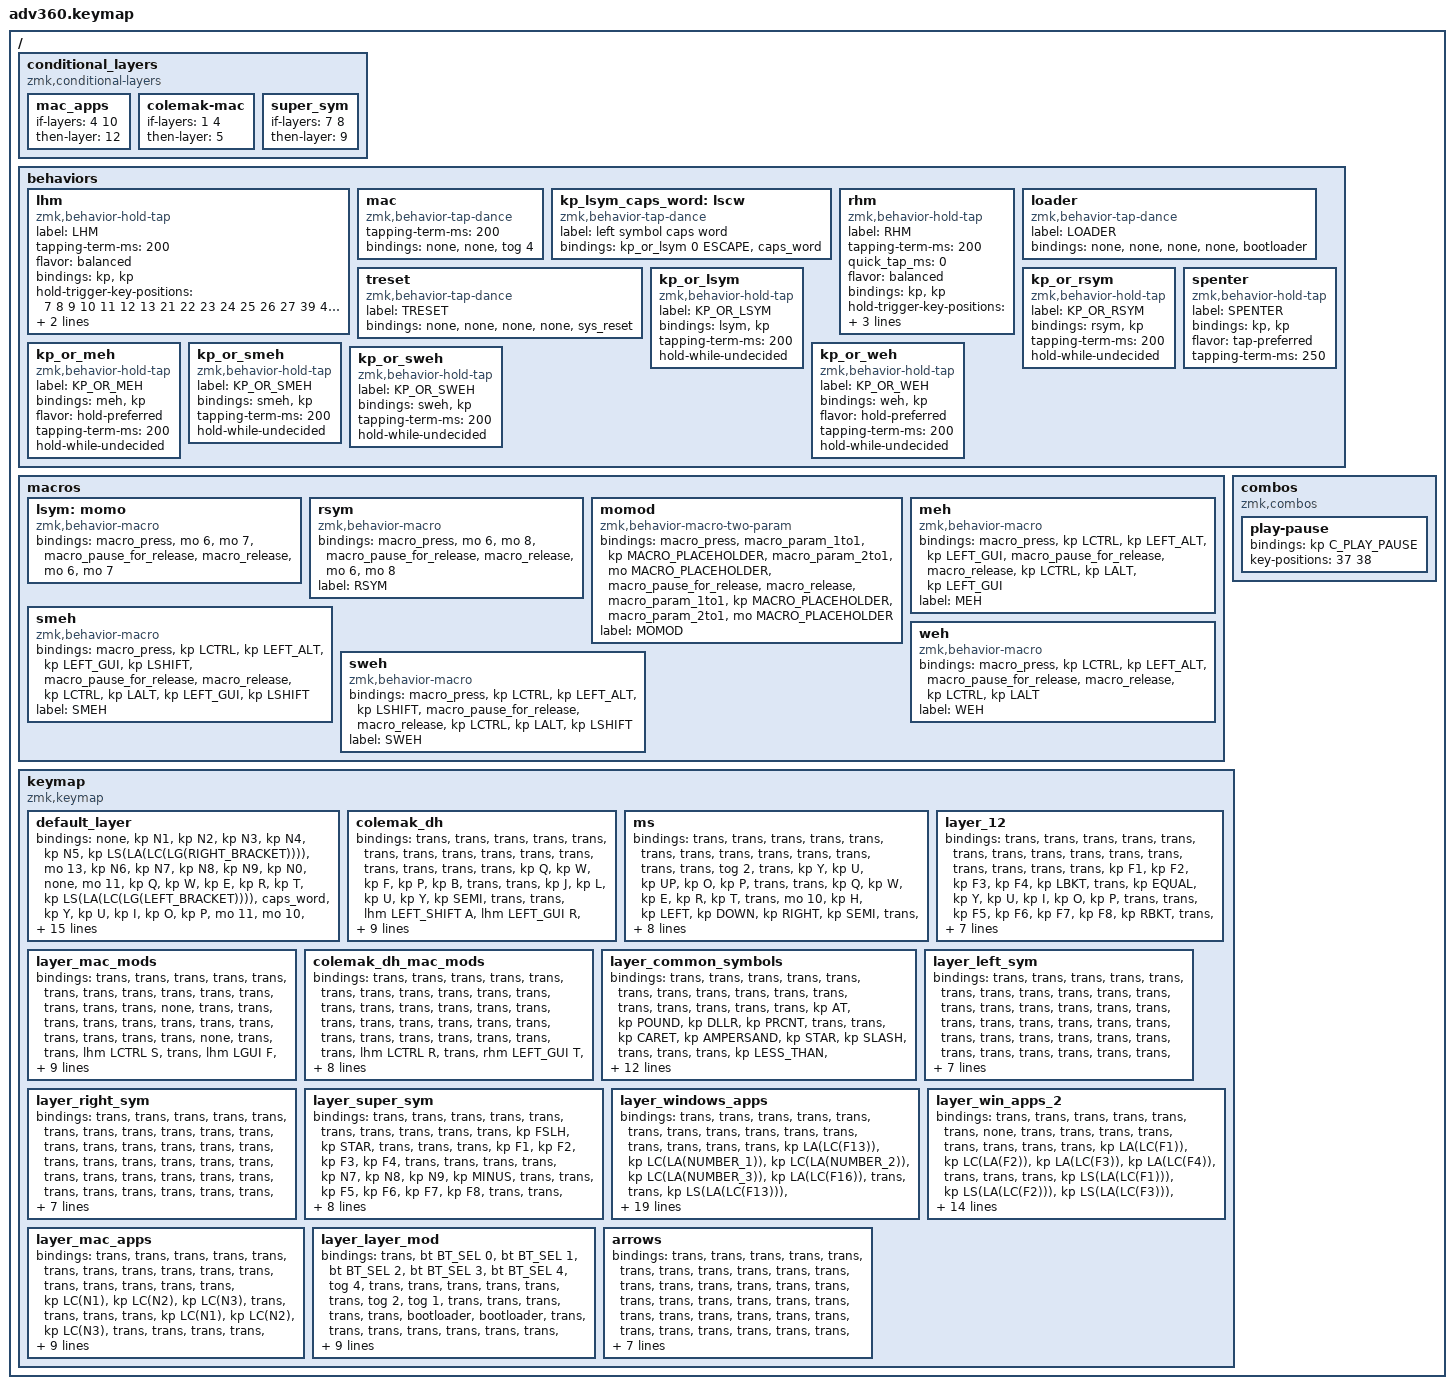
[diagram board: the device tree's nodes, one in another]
/*
 * Copyright (c) 2020 The ZMK Contributors
 *
 * SPDX-License-Identifier: MIT
 */
/* THIS FILE WAS GENERATED!
 *
 * This file was generated automatically. You may or may not want to
 * edit it directly.
 */

#include <behaviors.dtsi>
#include <dt-bindings/zmk/backlight.h>
#include <dt-bindings/zmk/bt.h>
#include <dt-bindings/zmk/keys.h>
#include <dt-bindings/zmk/rgb.h>

#define DEFAULT   0
#define MAC       1
#define SYM       2
#define LSYM      3
#define RSYM      4
#define ESYM      5
#define WINAPPS   6
#define MACAPPS   7
#define MOD       8

/ {
    conditional_layers {
        compatible = "zmk,conditional-layers";

        mac_apps {
            if-layers = <4 10>;
            then-layer = <12>;
        };

        colemak-mac {
            if-layers = <1 4>;
            then-layer = <5>;
        };

        super_sym {
            if-layers = <7 8>;
            then-layer = <9>;
        };
    };

    behaviors {
        lhm: lhm {
            compatible = "zmk,behavior-hold-tap";
            label = "LHM";
            #binding-cells = <2>;
            tapping-term-ms = <200>;
            flavor = "balanced";
            bindings = <&kp>, <&kp>;

            hold-trigger-key-positions = <7 8 9 10 11 12 13 21 22 23 24 25 26 27 39 40 41 42 43 44 45 54 55 56 57 58 59 71 72 73 74 75>;
            require-prior-idle-ms = <500>;
            quick-tap-ms = <175>;
        };

        mac: mac {
            compatible = "zmk,behavior-tap-dance";
            #binding-cells = <0>;
            tapping-term-ms = <200>;
            bindings = <&none>, <&none>, <&tog 4>;
        };

        kp_lsym_caps_word: lscw {
            compatible = "zmk,behavior-tap-dance";
            label = "left symbol caps word";
            #binding-cells = <0>;
            bindings = <&kp_or_lsym 0 ESCAPE>, <&caps_word>;
        };

        rhm: rhm {
            compatible = "zmk,behavior-hold-tap";
            label = "RHM";
            #binding-cells = <2>;
            tapping-term-ms = <200>;
            quick_tap_ms = <0>;
            flavor = "balanced";
            bindings = <&kp>, <&kp>;

            hold-trigger-key-positions = <0 1 2 3 4 5 6 16 17 18 19 20 14 15 16 17 18 19 20 28 29 30 31 32 33 34 46 47 48 49 50 51 60 61 62 63 64>;
            require-prior-idle-ms = <500>;
            quick-tap-ms = <175>;
        };

        loader: loader {
            compatible = "zmk,behavior-tap-dance";
            label = "LOADER";
            #binding-cells = <0>;
            bindings = <&none>, <&none>, <&none>, <&none>, <&bootloader>;
        };

        treset: treset {
            compatible = "zmk,behavior-tap-dance";
            label = "TRESET";
            #binding-cells = <0>;
            bindings = <&none>, <&none>, <&none>, <&none>, <&sys_reset>;
        };

        kp_or_lsym: kp_or_lsym {
            compatible = "zmk,behavior-hold-tap";
            label = "KP_OR_LSYM";
            bindings = <&lsym>, <&kp>;

            #binding-cells = <2>;
            tapping-term-ms = <200>;
            hold-while-undecided;
        };

        kp_or_rsym: kp_or_rsym {
            compatible = "zmk,behavior-hold-tap";
            label = "KP_OR_RSYM";
            bindings = <&rsym>, <&kp>;

            #binding-cells = <2>;
            tapping-term-ms = <200>;
            hold-while-undecided;
        };

        spenter: spenter {
            compatible = "zmk,behavior-hold-tap";
            label = "SPENTER";
            bindings = <&kp>, <&kp>;

            #binding-cells = <2>;
            flavor = "tap-preferred";
            tapping-term-ms = <250>;
        };

        kp_or_meh: kp_or_meh {
            compatible = "zmk,behavior-hold-tap";
            label = "KP_OR_MEH";
            bindings = <&meh>, <&kp>;

            #binding-cells = <2>;
            flavor = "hold-preferred";
            tapping-term-ms = <200>;
            hold-while-undecided;
        };

        kp_or_smeh: kp_or_smeh {
            compatible = "zmk,behavior-hold-tap";
            label = "KP_OR_SMEH";
            bindings = <&smeh>, <&kp>;

            #binding-cells = <2>;
            tapping-term-ms = <200>;
            hold-while-undecided;
        };

        kp_or_weh: kp_or_weh {
            compatible = "zmk,behavior-hold-tap";
            label = "KP_OR_WEH";
            bindings = <&weh>, <&kp>;

            #binding-cells = <2>;
            flavor = "hold-preferred";
            tapping-term-ms = <200>;
            hold-while-undecided;
        };

        kp_or_sweh: kp_or_sweh {
            compatible = "zmk,behavior-hold-tap";
            label = "KP_OR_SWEH";
            bindings = <&sweh>, <&kp>;

            #binding-cells = <2>;
            tapping-term-ms = <200>;
            hold-while-undecided;
        };
    };

    macros {
        lsym: momo {
            compatible = "zmk,behavior-macro";
            #binding-cells = <0>;
            bindings =
                <&macro_press>,
                <&mo 6 &mo 7>,
                <&macro_pause_for_release>,
                <&macro_release>,
                <&mo 6 &mo 7>;
        };

        rsym: rsym {
            compatible = "zmk,behavior-macro";
            #binding-cells = <0>;
            bindings =
                <&macro_press>,
                <&mo 6 &mo 8>,
                <&macro_pause_for_release>,
                <&macro_release>,
                <&mo 6 &mo 8>;

            label = "RSYM";
        };

        momod: momod {
            compatible = "zmk,behavior-macro-two-param";
            #binding-cells = <2>;
            bindings =
                <&macro_press>,
                <&macro_param_1to1 &kp MACRO_PLACEHOLDER &macro_param_2to1 &mo MACRO_PLACEHOLDER>,
                <&macro_pause_for_release>,
                <&macro_release>,
                <&macro_param_1to1 &kp MACRO_PLACEHOLDER &macro_param_2to1 &mo MACRO_PLACEHOLDER>;

            label = "MOMOD";
        };

        meh: meh {
            compatible = "zmk,behavior-macro";
            #binding-cells = <0>;
            bindings =
                <&macro_press>,
                <&kp LCTRL &kp LEFT_ALT &kp LEFT_GUI>,
                <&macro_pause_for_release>,
                <&macro_release>,
                <&kp LCTRL &kp LALT &kp LEFT_GUI>;

            label = "MEH";
        };

        smeh: smeh {
            compatible = "zmk,behavior-macro";
            #binding-cells = <0>;
            bindings =
                <&macro_press>,
                <&kp LCTRL &kp LEFT_ALT &kp LEFT_GUI &kp LSHIFT>,
                <&macro_pause_for_release>,
                <&macro_release>,
                <&kp LCTRL &kp LALT &kp LEFT_GUI &kp LSHIFT>;

            label = "SMEH";
        };

        weh: weh {
            compatible = "zmk,behavior-macro";
            #binding-cells = <0>;
            bindings =
                <&macro_press>,
                <&kp LCTRL &kp LEFT_ALT>,
                <&macro_pause_for_release>,
                <&macro_release>,
                <&kp LCTRL &kp LALT>;

            label = "WEH";
        };

        sweh: sweh {
            compatible = "zmk,behavior-macro";
            #binding-cells = <0>;
            bindings =
                <&macro_press>,
                <&kp LCTRL &kp LEFT_ALT &kp LSHIFT>,
                <&macro_pause_for_release>,
                <&macro_release>,
                <&kp LCTRL &kp LALT &kp LSHIFT>;

            label = "SWEH";
        };
    };

    combos {
        compatible = "zmk,combos";

        play-pause {
            bindings = <&kp C_PLAY_PAUSE>;
            key-positions = <37 38>;
        };
    };

    keymap {
        compatible = "zmk,keymap";

        default_layer {
            bindings = <
&none      &kp N1         &kp N2         &kp N3         &kp N4        &kp N5  &kp LS(LA(LC(LG(RIGHT_BRACKET))))                                                                                                                       &mo 13      &kp N6  &kp N7        &kp N8       &kp N9           &kp N0                 &none
&mo 11     &kp Q          &kp W          &kp E          &kp R         &kp T   &kp LS(LA(LC(LG(LEFT_BRACKET))))                                                                                                                        &caps_word  &kp Y   &kp U         &kp I        &kp O            &kp P                  &mo 11
&mo 10     &lhm LSHIFT A  &lhm LGUI S    &lhm LALT D    &lhm LCTRL F  &kp G   &kp DELETE                         &kp LS(LA(LC(LG(LEFT_BRACKET))))  &kp LS(LA(LC(LG(RIGHT_BRACKET))))      &kp C_VOLUME_DOWN     &kp C_VOLUME_UP       &kp LC(A)   &kp H   &rhm LCTRL J  &rhm LALT K  &rhm LEFT_GUI L  &rhm RIGHT_SHIFT SEMI  &mo 10
&kp LSHFT  &kp Z          &kp X          &kp C          &kp V         &kp B                                                                        &key_repeat                            &key_repeat                                             &kp N   &kp M         &kp COMMA    &kp DOT          &kp FSLH               &kp RSHFT
&mo 14     &kp GRAVE      &kp BACKSLASH  &kp LS(UNDER)  &kp EQUAL             &kp BSPC                           &kp_or_lsym 0 ESCAPE              &kp_or_weh 0 TAB                       &kp_or_sweh 0 DELETE  &kp_or_rsym 0 RETURN  &kp SPACE           &kp LS(PLUS)  &kp MINUS    &kp COLON        &kp SINGLE_QUOTE       &mo 14
            >;
        };

        colemak_dh {
            bindings = <
&trans  &trans             &trans           &trans           &trans        &trans  &trans                                      &trans  &trans  &trans        &trans           &trans           &trans             &trans
&trans  &kp Q              &kp W            &kp F            &kp P         &kp B   &trans                                      &trans  &kp J   &kp L         &kp U            &kp Y            &kp SEMI           &trans
&trans  &lhm LEFT_SHIFT A  &lhm LEFT_GUI R  &lhm LEFT_ALT S  &lhm LCTRL T  &kp G   &trans  &trans  &trans      &trans  &trans  &trans  &kp M   &rhm LCTRL N  &rhm LEFT_ALT E  &rhm LEFT_GUI I  &rhm LEFT_SHIFT O  &trans
&trans  &kp Z              &kp X            &kp C            &kp D         &kp V                   &trans      &trans                  &kp K   &kp H         &kp COMMA        &kp DOT          &kp FSLH           &trans
&trans  &trans             &trans           &trans           &trans                &trans  &trans  &trans      &trans  &trans  &trans          &trans        &trans           &trans           &trans             &trans
            >;
        };

        ms {
            bindings = <
&trans  &trans  &trans    &trans     &trans     &trans    &trans                                                &trans     &trans  &trans  &trans  &trans  &trans  &tog 2
&trans  &kp Y   &kp U     &kp UP     &kp O      &kp P     &trans                                                &trans     &kp Q   &kp W   &kp E   &kp R   &kp T   &trans
&mo 10  &kp H   &kp LEFT  &kp DOWN   &kp RIGHT  &kp SEMI  &trans  &kp ENTER  &trans         &kp LGUI   &trans   &trans     &kp A   &kp S   &kp D   &kp F   &kp G   &mo 10
&trans  &kp N   &kp M     &kp COMMA  &kp DOT    &kp FSLH                     &trans         &kp LALT                       &kp Z   &kp X   &kp C   &kp V   &kp B   &trans
&trans  &trans  &trans    &trans     &trans               &mo 3   &kp ESC    &kp ENTER      &kp LCTRL  &kp TAB  &kp SPACE          &trans  &trans  &trans  &trans  &trans
            >;
        };

        layer_12 {
            bindings = <
&trans  &trans  &trans   &trans   &trans   &trans     &trans                                      &trans     &trans  &trans  &trans     &trans   &trans    &trans
&trans  &kp F1  &kp F2   &kp F3   &kp F4   &kp LBKT   &trans                                      &kp EQUAL  &kp Y   &kp U   &kp I      &kp O    &kp P     &trans
&trans  &kp F5  &kp F6   &kp F7   &kp F8   &kp RBKT   &trans  &trans  &trans      &trans  &trans  &trans     &kp H   &kp J   &kp K      &kp L    &kp SEMI  &trans
&trans  &kp F9  &kp F10  &kp F11  &kp F12  &kp MINUS                  &trans      &trans                     &kp N   &kp M   &kp COMMA  &kp DOT  &kp FSLH  &trans
&trans  &trans  &trans   &trans   &trans              &trans  &trans  &trans      &trans  &trans  &trans             &trans  &trans     &trans   &trans    &trans
            >;
        };

        layer_mac_mods {
            bindings = <
&trans  &trans  &trans        &trans  &trans       &trans  &trans                                                           &trans     &trans  &trans           &trans  &trans        &trans  &trans
&none   &trans  &trans        &trans  &trans       &trans  &trans                                                           &trans     &trans  &trans           &trans  &trans        &trans  &none
&trans  &trans  &lhm LCTRL S  &trans  &lhm LGUI F  &trans  &trans  &trans  &trans                &trans             &trans  &kp LC(A)  &trans  &rhm LEFT_GUI J  &trans  &rhm LCTRL L  &trans  &trans
&trans  &trans  &trans        &trans  &trans       &trans                  &trans                &trans                                &trans  &trans           &trans  &trans        &trans  &trans
&trans  &trans  &trans        &trans  &trans               &trans  &trans  &kp_or_meh 0 TAB      &kp_or_smeh 0 DEL  &trans  &trans             &trans           &trans  &trans        &trans  &trans
            >;
        };

        colemak_dh_mac_mods {
            bindings = <
&trans  &trans  &trans        &trans  &trans           &trans  &trans                                      &trans  &trans  &trans           &trans  &trans        &trans  &trans
&trans  &trans  &trans        &trans  &trans           &trans  &trans                                      &trans  &trans  &trans           &trans  &trans        &trans  &trans
&trans  &trans  &lhm LCTRL R  &trans  &rhm LEFT_GUI T  &trans  &trans  &trans  &trans      &trans  &trans  &trans  &trans  &rhm LEFT_GUI N  &trans  &rhm LCTRL I  &trans  &trans
&trans  &trans  &trans        &trans  &trans           &trans                  &trans      &trans                  &trans  &trans           &trans  &trans        &trans  &trans
&trans  &trans  &trans        &trans  &trans                   &trans  &trans  &trans      &trans  &trans  &trans          &trans           &trans  &trans        &trans  &trans
            >;
        };

        layer_common_symbols {
            bindings = <
&trans  &trans            &trans          &trans            &trans                &trans     &trans                                       &trans   &trans     &trans                 &trans             &trans           &trans             &trans
&trans  &trans            &kp AT          &kp POUND         &kp DLLR              &kp PRCNT  &trans                                       &trans   &kp CARET  &kp AMPERSAND          &kp STAR           &kp SLASH        &trans             &trans
&trans  &kp LESS_THAN     &kp LEFT_BRACE  &kp LEFT_BRACKET  &kp LEFT_PARENTHESIS  &trans     &trans   &trans  &trans      &trans  &trans  &trans   &trans     &kp RIGHT_PARENTHESIS  &kp RIGHT_BRACKET  &kp RIGHT_BRACE  &kp GREATER_THAN   &trans
&trans  &kp SINGLE_QUOTE  &kp BACKSLASH   &kp GRAVE         &kp TILDE             &trans                      &trans      &trans                   &trans     &kp QMARK              &kp EXCL           &kp PIPE         &kp DOUBLE_QUOTES  &trans
&trans  &trans            &trans          &trans            &trans                           &kp TAB  &trans  &trans      &trans  &trans  &kp ESC             &trans                 &trans             &trans           &trans             &trans
            >;
        };

        layer_left_sym {
            bindings = <
&trans  &trans  &trans  &trans  &trans  &trans  &trans                                      &trans  &trans  &trans  &trans  &trans  &trans  &trans
&trans  &trans  &trans  &trans  &trans  &trans  &trans                                      &trans  &trans  &trans  &trans  &trans  &trans  &trans
&trans  &trans  &trans  &trans  &trans  &trans  &trans  &trans  &trans      &trans  &trans  &trans  &trans  &trans  &trans  &trans  &trans  &trans
&trans  &trans  &trans  &trans  &trans  &trans                  &trans      &trans                  &trans  &trans  &trans  &trans  &trans  &trans
&trans  &trans  &trans  &trans  &trans          &trans  &trans  &trans      &trans  &trans  &trans          &trans  &trans  &trans  &trans  &trans
            >;
        };

        layer_right_sym {
            bindings = <
&trans  &trans  &trans  &trans  &trans  &trans  &trans                                      &trans  &trans  &trans  &trans  &trans  &trans  &trans
&trans  &trans  &trans  &trans  &trans  &trans  &trans                                      &trans  &trans  &trans  &trans  &trans  &trans  &trans
&trans  &trans  &trans  &trans  &trans  &trans  &trans  &trans  &trans      &trans  &trans  &trans  &trans  &trans  &trans  &trans  &trans  &trans
&trans  &trans  &trans  &trans  &trans  &trans                  &trans      &trans                  &trans  &trans  &trans  &trans  &trans  &trans
&trans  &trans  &trans  &trans  &trans          &trans  &trans  &trans      &trans  &trans  &trans          &trans  &trans  &trans  &trans  &trans
            >;
        };

        layer_super_sym {
            bindings = <
&trans  &trans  &trans   &trans   &trans   &trans  &trans                                      &trans  &trans  &trans        &kp FSLH  &kp STAR  &trans     &trans
&trans  &kp F1  &kp F2   &kp F3   &kp F4   &trans  &trans                                      &trans  &trans  &kp N7        &kp N8    &kp N9    &kp MINUS  &trans
&trans  &kp F5  &kp F6   &kp F7   &kp F8   &trans  &trans  &trans  &trans      &trans  &trans  &trans  &trans  &kp N4        &kp N5    &kp N6    &kp PLUS   &kp BSPC
&trans  &kp F9  &kp F10  &kp F11  &kp F12  &trans                  &trans      &trans                  &trans  &kp NUMBER_1  &kp N2    &kp N3    &kp ENTER  &trans
&trans  &trans  &trans   &trans   &trans           &trans  &trans  &trans      &trans  &trans  &trans          &trans        &kp N0    &kp DOT   &trans     &trans
            >;
        };

        layer_windows_apps {
            bindings = <
&trans  &trans           &trans                &trans                &trans                &trans           &trans                                      &trans  &trans               &trans                    &trans                    &trans                    &trans               &trans
&trans  &kp LA(LC(F13))  &kp LC(LA(NUMBER_1))  &kp LC(LA(NUMBER_2))  &kp LC(LA(NUMBER_3))  &kp LA(LC(F16))  &trans                                      &trans  &kp LS(LA(LC(F13)))  &kp LC(LA(LS(NUMBER_1)))  &kp LC(LA(LS(NUMBER_2)))  &kp LC(LA(LS(NUMBER_3)))  &kp LC(LS(LA(F16)))  &trans
&trans  &kp LA(LC(F14))  &kp LC(LA(NUMBER_4))  &kp LC(LA(N5))        &kp LC(LA(NUMBER_6))  &kp LA(LC(F17))  &trans  &trans  &trans      &trans  &trans  &trans  &kp LS(LC(LA(F14)))  &kp LS(LA(LC(NUMBER_4)))  &kp LC(LA(LS(N5)))        &kp LC(LS(LA(NUMBER_6)))  &kp LC(LA(LS(F17)))  &trans
&trans  &kp LA(LC(F15))  &kp LC(LA(N7))        &kp LC(LA(N8))        &kp LC(LA(N9))        &kp LC(LA(F18))                  &trans      &trans                  &kp LC(LA(LS(F15)))  &kp LC(LA(LS(N7)))        &kp LC(LA(LS(N8)))        &kp LC(LA(LS(N9)))        &kp LC(LA(LS(F18)))  &trans
&trans  &trans           &trans                &trans                &trans                                 &trans  &trans  &trans      &trans  &trans  &trans                       &trans                    &trans                    &trans                    &trans               &trans
            >;
        };

        layer_win_apps_2 {
            bindings = <
&trans  &trans          &trans           &trans           &trans           &trans  &none                                       &trans  &trans              &trans               &trans               &trans               &trans  &trans
&trans  &kp LA(LC(F1))  &kp LC(LA(F2))   &kp LA(LC(F3))   &kp LA(LC(F4))   &trans  &trans                                      &trans  &kp LS(LA(LC(F1)))  &kp LS(LA(LC(F2)))   &kp LS(LA(LC(F3)))   &kp LS(LA(LC(F4)))   &trans  &trans
&trans  &kp LC(LA(F5))  &kp LC(LA(F6))   &kp LC(LA(F7))   &kp LC(LA(F8))   &trans  &trans  &trans  &trans      &trans  &trans  &trans  &kp LS(LA(LC(F5)))  &kp LS(LA(LC(F6)))   &kp LS(LA(LC(F7)))   &kp LS(LA(LC(F8)))   &trans  &trans
&trans  &kp LC(LA(F9))  &kp LC(LA(F10))  &kp LC(LA(F11))  &kp LC(LA(F12))  &trans                  &trans      &trans                  &kp LS(LA(LC(F9)))  &kp LS(LA(LC(F10)))  &kp LS(LA(LC(F11)))  &kp LS(LA(LC(F12)))  &trans  &trans
&trans  &trans          &trans           &trans           &trans                   &trans  &trans  &trans      &trans  &trans  &trans                      &trans               &trans               &trans               &trans  &trans
            >;
        };

        layer_mac_apps {
            bindings = <
&trans  &trans  &trans      &trans      &trans      &trans  &trans                                      &trans  &trans  &trans      &trans      &trans      &trans  &trans
&trans  &trans  &kp LC(N1)  &kp LC(N2)  &kp LC(N3)  &trans  &trans                                      &trans  &trans  &kp LC(N1)  &kp LC(N2)  &kp LC(N3)  &trans  &trans
&trans  &trans  &kp LC(N4)  &kp LC(N5)  &kp LC(N6)  &trans  &trans  &trans  &trans      &trans  &trans  &trans  &trans  &kp LC(N4)  &kp LC(N5)  &kp LC(N6)  &trans  &trans
&trans  &trans  &kp LC(N7)  &kp LC(N8)  &kp LC(N9)  &trans                  &trans      &trans                  &trans  &kp LC(N7)  &kp LC(N8)  &kp LC(N9)  &trans  &trans
&trans  &trans  &trans      &trans      &trans              &trans  &trans  &trans      &trans  &trans  &trans          &trans      &trans      &trans      &trans  &trans
            >;
        };

        layer_layer_mod {
            bindings = <
&trans  &bt BT_SEL 0  &bt BT_SEL 1  &bt BT_SEL 2  &bt BT_SEL 3  &bt BT_SEL 4  &tog 4                                                   &trans           &trans  &trans      &trans      &trans  &trans  &tog 2
&tog 1  &trans        &trans        &trans        &trans        &trans        &bootloader                                              &bootloader      &trans  &trans      &trans      &trans  &trans  &trans
&trans  &trans        &trans        &trans        &trans        &trans        &sys_reset   &trans  &trans      &bt BT_CLR  &trans      &sys_reset       &trans  &trans      &trans      &trans  &trans  &trans
&trans  &trans        &trans        &trans        &trans        &trans                             &trans      &trans                                   &trans  &trans      &trans      &trans  &trans  &trans
&trans  &trans        &trans        &trans        &trans                      &trans       &trans  &trans      &trans      &bl BL_TOG  &rgb_ug RGB_TOG          &bl BL_INC  &bl BL_DEC  &trans  &trans  &trans
            >;
        };

        arrows {
            bindings = <
&trans  &trans  &trans  &trans    &trans     &trans  &trans                                      &trans  &trans  &trans  &trans    &trans  &trans  &trans
&trans  &trans  &trans  &trans    &trans     &trans  &trans                                      &trans  &trans  &trans  &trans    &trans  &trans  &trans
&trans  &trans  &trans  &trans    &trans     &trans  &trans  &trans  &trans      &trans  &trans  &trans  &trans  &trans  &trans    &trans  &trans  &trans
&trans  &trans  &trans  &trans    &trans     &trans                  &trans      &trans                  &trans  &trans  &trans    &trans  &trans  &trans
&trans  &trans  &trans  &kp LEFT  &kp RIGHT          &trans  &trans  &trans      &trans  &trans  &trans          &kp UP  &kp DOWN  &trans  &trans  &trans
            >;
        };
    };
};
